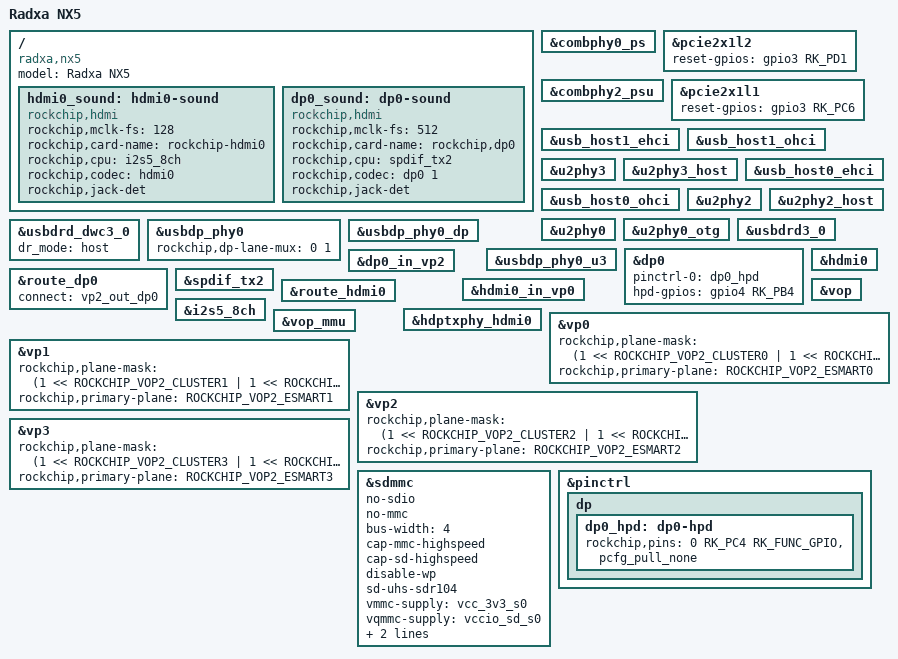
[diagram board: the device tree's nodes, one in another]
// SPDX-License-Identifier: (GPL-2.0+ OR MIT)
/*
 * Copyright (c) 2022 Rockchip Electronics Co., Ltd.
 * Copyright (c) 2022 Radxa Limited
 *
 */

/dts-v1/;

#include "rk3588s-radxa-nx5-module.dtsi"

/ {
	model = "Radxa NX5";
	compatible = "radxa,nx5", "rockchip,rk3588";

	hdmi0_sound: hdmi0-sound {
		status = "okay";
		compatible = "rockchip,hdmi";
		rockchip,mclk-fs = <128>;
		rockchip,card-name = "rockchip-hdmi0";
		rockchip,cpu = <&i2s5_8ch>;
		rockchip,codec = <&hdmi0>;
		rockchip,jack-det;
	};

	dp0_sound: dp0-sound {
		status = "okay";
		compatible = "rockchip,hdmi";
		rockchip,mclk-fs = <512>;
		rockchip,card-name= "rockchip,dp0";
		rockchip,cpu = <&spdif_tx2>;
		rockchip,codec = <&dp0 1>;
		rockchip,jack-det;
	};
};

&combphy0_ps {
	status = "okay";
};

&pcie2x1l2 {
	reset-gpios = <&gpio3 RK_PD1 GPIO_ACTIVE_HIGH>;
	status = "okay";
};

&combphy2_psu {
	status = "okay";
};

&pcie2x1l1 {
	reset-gpios = <&gpio3 RK_PC6 GPIO_ACTIVE_HIGH>;
	status = "okay";
};

&usb_host1_ehci {
	status = "okay";
};

&usb_host1_ohci {
	status = "okay";
};

&u2phy3 {
	status = "okay";
};

&u2phy3_host {
	status = "okay";
};

&usb_host0_ehci {
	status = "okay";
};

&usb_host0_ohci {
	status = "okay";
};

&u2phy2 {
	status = "okay";
};

&u2phy2_host {
	status = "okay";
};

&u2phy0 {
	status = "okay";
};

&u2phy0_otg {
	status = "okay";
};

&usbdrd3_0 {
	status = "okay";
};

&usbdrd_dwc3_0 {
	status = "okay";
	dr_mode = "host";
};

&usbdp_phy0 {
	status = "okay";
	rockchip,dp-lane-mux = < 0 1 >;
};

&usbdp_phy0_dp {
	status = "okay";
};

&usbdp_phy0_u3 {
	status = "okay";
};

&dp0 {
	status = "okay";
	pinctrl-names = "default";
	pinctrl-0 = <&dp0_hpd>;
	hpd-gpios = <&gpio4 RK_PB4 GPIO_ACTIVE_HIGH>;
};

&dp0_in_vp2 {
	status = "okay";
};

&route_dp0 {
	status = "okay";
	connect = <&vp2_out_dp0>;
};

&spdif_tx2 {
	status = "okay";
};

&hdmi0 {
	status = "okay";
};

&hdmi0_in_vp0 {
	status = "okay";
};

&route_hdmi0 {
	status = "okay";
};

&hdptxphy_hdmi0 {
	status = "okay";
};

&i2s5_8ch {
	status = "okay";
};

&vop {
	status = "okay";
};

&vop_mmu {
	status = "okay";
};

&vp0 {
	rockchip,plane-mask = <(1 << ROCKCHIP_VOP2_CLUSTER0 | 1 << ROCKCHIP_VOP2_ESMART0)>;
	rockchip,primary-plane = <ROCKCHIP_VOP2_ESMART0>;
};

&vp1 {
	rockchip,plane-mask = <(1 << ROCKCHIP_VOP2_CLUSTER1 | 1 << ROCKCHIP_VOP2_ESMART1)>;
	rockchip,primary-plane = <ROCKCHIP_VOP2_ESMART1>;
};

&vp2 {
	rockchip,plane-mask = <(1 << ROCKCHIP_VOP2_CLUSTER2 | 1 << ROCKCHIP_VOP2_ESMART2)>;
	rockchip,primary-plane = <ROCKCHIP_VOP2_ESMART2>;
};

&vp3 {
	rockchip,plane-mask = <(1 << ROCKCHIP_VOP2_CLUSTER3 | 1 << ROCKCHIP_VOP2_ESMART3)>;
	rockchip,primary-plane = <ROCKCHIP_VOP2_ESMART3>;
};

&sdmmc {
	no-sdio;
	no-mmc;
	bus-width = <4>;
	cap-mmc-highspeed;
	cap-sd-highspeed;
	disable-wp;
	sd-uhs-sdr104;
	vmmc-supply = <&vcc_3v3_s0>;
	vqmmc-supply = <&vccio_sd_s0>;
	pinctrl-names = "default";
	pinctrl-0 = <&sdmmc_bus4 &sdmmc_clk &sdmmc_cmd &sdmmc_det>;
	status = "okay";
};

&pinctrl {
	dp {
		dp0_hpd: dp0-hpd {
			rockchip,pins = <0 RK_PC4 RK_FUNC_GPIO &pcfg_pull_none>;
		};
	};
};
